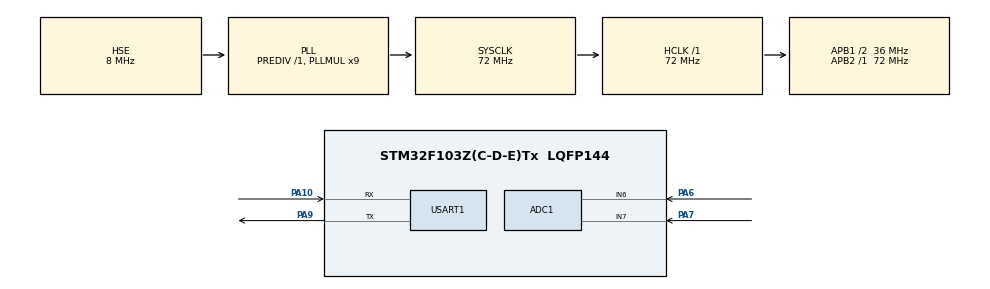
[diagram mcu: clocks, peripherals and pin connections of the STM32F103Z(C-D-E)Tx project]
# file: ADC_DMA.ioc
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ADC1.Channel-8\#ChannelRegularConversion=ADC_CHANNEL_6
ADC1.Channel-9\#ChannelRegularConversion=ADC_CHANNEL_7
ADC1.ContinuousConvMode=ENABLE
ADC1.DataAlign=ADC_DATAALIGN_RIGHT
ADC1.DiscontinuousConvMode=DISABLE
ADC1.EnableAnalogWatchDog=false
ADC1.EnableRegularConversion=ENABLE
ADC1.ExternalTrigConv=ADC_SOFTWARE_START
ADC1.ExternalTrigConvEdgeChoice=NONE
ADC1.InjNumberOfConversion=0
ADC1.NbrOfConversion=2
ADC1.NbrOfConversionFlag=1
ADC1.Rank-8\#ChannelRegularConversion=1
ADC1.Rank-9\#ChannelRegularConversion=2
ADC1.SamplingTime-8\#ChannelRegularConversion=ADC_SAMPLETIME_1CYCLE_5
ADC1.SamplingTime-9\#ChannelRegularConversion=ADC_SAMPLETIME_1CYCLE_5
ADC1.ScanConvMode=ADC_SCAN_ENABLE
ADC1.master=1
Dma.ADC1.0.Direction=DMA_PERIPH_TO_MEMORY
Dma.ADC1.0.Instance=DMA1_Channel1
Dma.ADC1.0.MemDataAlignment=DMA_MDATAALIGN_WORD
Dma.ADC1.0.MemInc=DMA_MINC_ENABLE
Dma.ADC1.0.Mode=DMA_CIRCULAR
Dma.ADC1.0.PeriphDataAlignment=DMA_PDATAALIGN_WORD
Dma.ADC1.0.PeriphInc=DMA_PINC_DISABLE
Dma.ADC1.0.Priority=DMA_PRIORITY_HIGH
Dma.Request0=ADC1
Mcu.Family=STM32F1
Mcu.Name=STM32F103Z(C-D-E)Tx
Mcu.Package=LQFP144
NVIC.DMA1_Channel1_IRQn=true\:0\:0\:false\:false\:true
NVIC.PriorityGroup=NVIC_PRIORITYGROUP_4
OSC_IN.Mode=HSE-External-Oscillator
OSC_IN.Signal=RCC_OSC_IN
OSC_OUT.Mode=HSE-External-Oscillator
OSC_OUT.Signal=RCC_OSC_OUT
PA10.Mode=Asynchronous
PA10.Signal=USART1_RX
PA6.Signal=ADCx_IN6
PA7.Signal=ADCx_IN7
PA9.Mode=Asynchronous
PA9.Signal=USART1_TX
ProjectManager.HeapSize=0x200
ProjectManager.StackSize=0x400
ProjectManager.TargetToolchain=MDK-ARM V5
RCC.ADCPresc=RCC_ADCPCLK2_DIV6
RCC.AHBFreq_Value=72000000
RCC.APB1CLKDivider=RCC_HCLK_DIV2
RCC.APB1Freq_Value=36000000
RCC.APB1TimFreq_Value=72000000
RCC.APB2Freq_Value=72000000
RCC.APB2TimFreq_Value=72000000
RCC.HCLKFreq_Value=72000000
RCC.HSIState=RCC_HSI_ON
RCC.PLLMUL=RCC_PLL_MUL9
RCC.PLLSourceVirtual=RCC_PLLSOURCE_HSE
RCC.SYSCLKFreq_VALUE=72000000
RCC.SYSCLKSource=RCC_SYSCLKSOURCE_PLLCLK
RCC.USBFreq_Value=72000000
SH.ADCx_IN6.0=ADC1_IN6,IN6
SH.ADCx_IN7.0=ADC1_IN7,IN7
VP_SYS_VS_ND.Mode=No_Debug
board=ADC_DMA

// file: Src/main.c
/**
  ******************************************************************************
  * File Name          : main.c
  * Description        : Main program body
  ******************************************************************************
  *
  * COPYRIGHT(c) 2017 STMicroelectronics
  *
  * Redistribution and use in source and binary forms, with or without modification,
  * are permitted provided that the following conditions are met:
  *   1. Redistributions of source code must retain the above copyright notice,
  *      this list of conditions and the following disclaimer.
  *   2. Redistributions in binary form must reproduce the above copyright notice,
  *      this list of conditions and the following disclaimer in the documentation
  *      and/or other materials provided with the distribution.
  *   3. Neither the name of STMicroelectronics nor the names of its contributors
  *      may be used to endorse or promote products derived from this software
  *      without specific prior written permission.
  *
  * THIS SOFTWARE IS PROVIDED BY THE COPYRIGHT HOLDERS AND CONTRIBUTORS "AS IS"
  * AND ANY EXPRESS OR IMPLIED WARRANTIES, INCLUDING, BUT NOT LIMITED TO, THE
  * IMPLIED WARRANTIES OF MERCHANTABILITY AND FITNESS FOR A PARTICULAR PURPOSE ARE
  * DISCLAIMED. IN NO EVENT SHALL THE COPYRIGHT HOLDER OR CONTRIBUTORS BE LIABLE
  * FOR ANY DIRECT, INDIRECT, INCIDENTAL, SPECIAL, EXEMPLARY, OR CONSEQUENTIAL
  * DAMAGES (INCLUDING, BUT NOT LIMITED TO, PROCUREMENT OF SUBSTITUTE GOODS OR
  * SERVICES; LOSS OF USE, DATA, OR PROFITS; OR BUSINESS INTERRUPTION) HOWEVER
  * CAUSED AND ON ANY THEORY OF LIABILITY, WHETHER IN CONTRACT, STRICT LIABILITY,
  * OR TORT (INCLUDING NEGLIGENCE OR OTHERWISE) ARISING IN ANY WAY OUT OF THE USE
  * OF THIS SOFTWARE, EVEN IF ADVISED OF THE POSSIBILITY OF SUCH DAMAGE.
  *
  ******************************************************************************
  */
#include "main.h"
#include "stm32f1xx_hal.h"
#include "adc.h"
#include "dma.h"
#include "usart.h"
#include "gpio.h"

/* USER CODE BEGIN PV */
/* Private variables ---------------------------------------------------------*/

/* USER CODE END PV */

void SystemClock_Config(void);
void Error_Handler(void);

/* USER CODE BEGIN PFP */
/* Private function prototypes -----------------------------------------------*/

/* USER CODE END PFP */

/* USER CODE BEGIN 0 */
  uint32_t ADC_Value[100];
  uint8_t i;
  uint32_t ad1, ad2;
/* USER CODE END 0 */

int main(void)
{

  /* MCU Configuration----------------------------------------------------------*/

  /* Reset of all peripherals, Initializes the Flash interface and the Systick. */
  HAL_Init();

  /* Configure the system clock */
  SystemClock_Config();

  /* Initialize all configured peripherals */
  MX_GPIO_Init();
  MX_DMA_Init();
  MX_USART1_UART_Init();
  MX_ADC1_Init();

  /* USER CODE BEGIN 2 */
  /*## Start the conversion process and enable interrupt ##*/
  HAL_ADC_Start_DMA(&hadc1, (uint32_t*)&ADC_Value, 100);

  /* USER CODE END 2 */

  /* Infinite loop */
  while (1)
  {

  /* USER CODE BEGIN 3 */
    HAL_Delay(500);
    for(i = 0, ad1 =0, ad2=0; i < 100;)
    {
      ad1 += ADC_Value[i++];
      ad2 += ADC_Value[i++];
    }
    ad1 /= 50;
    ad2 /= 50;

    printf("\r\n******** ADC DMA Example ********\r\n\r\n");
    printf(" AD1 value = %1.3fV \r\n", ad1 * 3.3f / 4096);
    printf(" AD2 value = %1.3fV \r\n", ad2 * 3.3f / 4096);
  }
  /* USER CODE END 3 */

}

/** System Clock Configuration
*/
void SystemClock_Config(void)
{

  RCC_OscInitTypeDef RCC_OscInitStruct;
  RCC_ClkInitTypeDef RCC_ClkInitStruct;
  RCC_PeriphCLKInitTypeDef PeriphClkInit;

    /**Initializes the CPU, AHB and APB busses clocks
    */
  RCC_OscInitStruct.OscillatorType = RCC_OSCILLATORTYPE_HSE;
  RCC_OscInitStruct.HSEState = RCC_HSE_ON;
  RCC_OscInitStruct.HSEPredivValue = RCC_HSE_PREDIV_DIV1;
  RCC_OscInitStruct.HSIState = RCC_HSI_ON;
  RCC_OscInitStruct.PLL.PLLState = RCC_PLL_ON;
  RCC_OscInitStruct.PLL.PLLSource = RCC_PLLSOURCE_HSE;
  RCC_OscInitStruct.PLL.PLLMUL = RCC_PLL_MUL9;
  if (HAL_RCC_OscConfig(&RCC_OscInitStruct) != HAL_OK)
  {
    Error_Handler();
  }

    /**Initializes the CPU, AHB and APB busses clocks
    */
  RCC_ClkInitStruct.ClockType = RCC_CLOCKTYPE_HCLK|RCC_CLOCKTYPE_SYSCLK
                              |RCC_CLOCKTYPE_PCLK1|RCC_CLOCKTYPE_PCLK2;
  RCC_ClkInitStruct.SYSCLKSource = RCC_SYSCLKSOURCE_PLLCLK;
  RCC_ClkInitStruct.AHBCLKDivider = RCC_SYSCLK_DIV1;
  RCC_ClkInitStruct.APB1CLKDivider = RCC_HCLK_DIV2;
  RCC_ClkInitStruct.APB2CLKDivider = RCC_HCLK_DIV1;

  if (HAL_RCC_ClockConfig(&RCC_ClkInitStruct, FLASH_LATENCY_2) != HAL_OK)
  {
    Error_Handler();
  }

  PeriphClkInit.PeriphClockSelection = RCC_PERIPHCLK_ADC;
  PeriphClkInit.AdcClockSelection = RCC_ADCPCLK2_DIV6;
  if (HAL_RCCEx_PeriphCLKConfig(&PeriphClkInit) != HAL_OK)
  {
    Error_Handler();
  }

    /**Configure the Systick interrupt time
    */
  HAL_SYSTICK_Config(HAL_RCC_GetHCLKFreq()/1000);

    /**Configure the Systick
    */
  HAL_SYSTICK_CLKSourceConfig(SYSTICK_CLKSOURCE_HCLK);

  /* SysTick_IRQn interrupt configuration */
  HAL_NVIC_SetPriority(SysTick_IRQn, 0, 0);
}

void Error_Handler(void)
{
  while(1)
  {
  }
}

/************************ (C) COPYRIGHT STMicroelectronics *****END OF FILE****/
